AUTOSAR XML (schema 4-3-0)
package /ComponentTypes
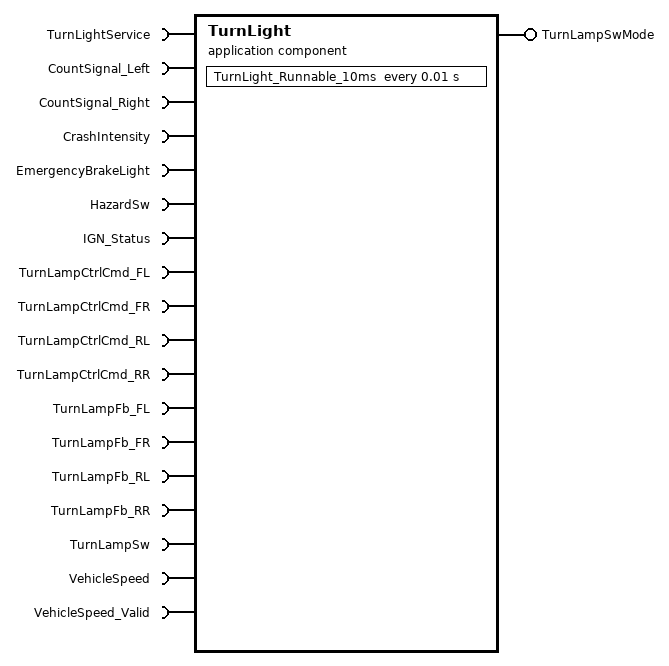
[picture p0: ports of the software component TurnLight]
  application sw component type TurnLight
    provide port TurnLampSwMode: nonqueued-sender-com-spec{data-element=u8_signa, init-value=0}, provided-interface=TurnLampSwMode
    18 x require port:
      TurnLightService: client-com-spec=TurnLightControl_Operation, required-interface=TurnLightService
      CountSignal_Left: nonqueued-receiver-com-spec{data-element=u8_Signal, init-value=0}, required-interface=CountSignal_Left
      CountSignal_Right: nonqueued-receiver-com-spec{data-element=u8_Signal, init-value=0}, required-interface=CountSignal_Right
      CrashIntensity: nonqueued-receiver-com-spec{data-element=u8_Signal, init-value=0}, required-interface=CrashIntensity
      EmergencyBrakeLight: nonqueued-receiver-com-spec{data-element=u8_Signal, init-value=0}, required-interface=EmergencyBrakeLight
      HazardSw: nonqueued-receiver-com-spec{data-element=u8_Signal, init-value=0}, required-interface=HazardSw
      IGN_Status: nonqueued-receiver-com-spec{data-element=u8_signal, init-value=0}, required-interface=IGN_Status
      TurnLampCtrlCmd_FL: nonqueued-receiver-com-spec{data-element=u8_signal, init-value=0}, required-interface=TurnLampCtrlCmd_FL
      TurnLampCtrlCmd_FR: nonqueued-receiver-com-spec{data-element=u8_signa, init-value=0}, required-interface=TurnLampCtrlCmd_FR
      TurnLampCtrlCmd_RL: nonqueued-receiver-com-spec{data-element=u8_signal, init-value=0}, required-interface=TurnLampCtrlCmd_RL
      TurnLampCtrlCmd_RR: nonqueued-receiver-com-spec{data-element=u8_signal, init-value=0}, required-interface=TurnLampCtrlCmd_RR
      TurnLampFb_FL: nonqueued-receiver-com-spec{data-element=u8_Signal, init-value=0}, required-interface=TurnLampFb_FL
      TurnLampFb_FR: nonqueued-receiver-com-spec{data-element=u8_Signal, init-value=0}, required-interface=TurnLampFb_FR
      TurnLampFb_RL: nonqueued-receiver-com-spec{data-element=u8_Signal, init-value=0}, required-interface=TurnLampFb_RL
      TurnLampFb_RR: nonqueued-receiver-com-spec{data-element=u8_Signal, init-value=0}, required-interface=TurnLampFb_RR
      TurnLampSw: nonqueued-receiver-com-spec{data-element=u8_Signal, init-value=0}, required-interface=TurnLampSw
      VehicleSpeed: nonqueued-receiver-com-spec{data-element=u16_signal, init-value=0}, required-interface=VehicleSpeed
      VehicleSpeed_Valid: nonqueued-receiver-com-spec{data-element=u8_Signal, init-value=0}, required-interface=VehicleSpeed_Valid
    behavior TurnLight_InternalBehavior
      timing event TMT_TurnLight_Runnable_10ms: start-on-event=TurnLight_Runnable_10ms, period=0.01
      runnable TurnLight_Runnable_10ms: minimum-start-interval=0.01
        data-receive-point-by-arguments:
          17 x access:
            REC_CountSignal_Left_u8_Signal: accessed-variable=CountSignal_Left.u8_Signal
            REC_CountSignal_Right_u8_Signal: accessed-variable=CountSignal_Right.u8_Signal
            REC_CrashIntensity_u8_Signal: accessed-variable=CrashIntensity.u8_Signal
            REC_EmergencyBrakeLight_u8_Signal: accessed-variable=EmergencyBrakeLight.u8_Signal
            REC_HazardSw_u8_Signal: accessed-variable=HazardSw.u8_Signal
            REC_IGN_Status_u8_signal: accessed-variable=IGN_Status.u8_signal
            REC_TurnLampCtrlCmd_FL_u8_signal: accessed-variable=TurnLampCtrlCmd_FL.u8_signal
            REC_TurnLampCtrlCmd_FR_u8_signa: accessed-variable=TurnLampCtrlCmd_FR.u8_signa
            REC_TurnLampCtrlCmd_RL_u8_signal: accessed-variable=TurnLampCtrlCmd_RL.u8_signal
            REC_TurnLampCtrlCmd_RR_u8_signal: accessed-variable=TurnLampCtrlCmd_RR.u8_signal
            REC_TurnLampFb_FL_u8_Signal: accessed-variable=TurnLampFb_FL.u8_Signal
            REC_TurnLampFb_FR_u8_Signal: accessed-variable=TurnLampFb_FR.u8_Signal
            REC_TurnLampFb_RL_u8_Signal: accessed-variable=TurnLampFb_RL.u8_Signal
            REC_TurnLampFb_RR_u8_Signal: accessed-variable=TurnLampFb_RR.u8_Signal
            REC_TurnLampSw_u8_Signal: accessed-variable=TurnLampSw.u8_Signal
            REC_VehicleSpeed_u16_signal: accessed-variable=VehicleSpeed.u16_signal
            REC_VehicleSpeed_Valid_u8_Signal: accessed-variable=VehicleSpeed_Valid.u8_Signal
        data-send-points:
          access SEND_TurnLampSwMode_u8_signa: accessed-variable=TurnLampSwMode.u8_signa
        sync call SC_TurnLightService_TurnLightControl_Operation: operation=TurnLightService.TurnLightControl_Operation, timeout=0.01
  swc implementation TurnLight_Implementation: behavior=TurnLight_InternalBehavior
